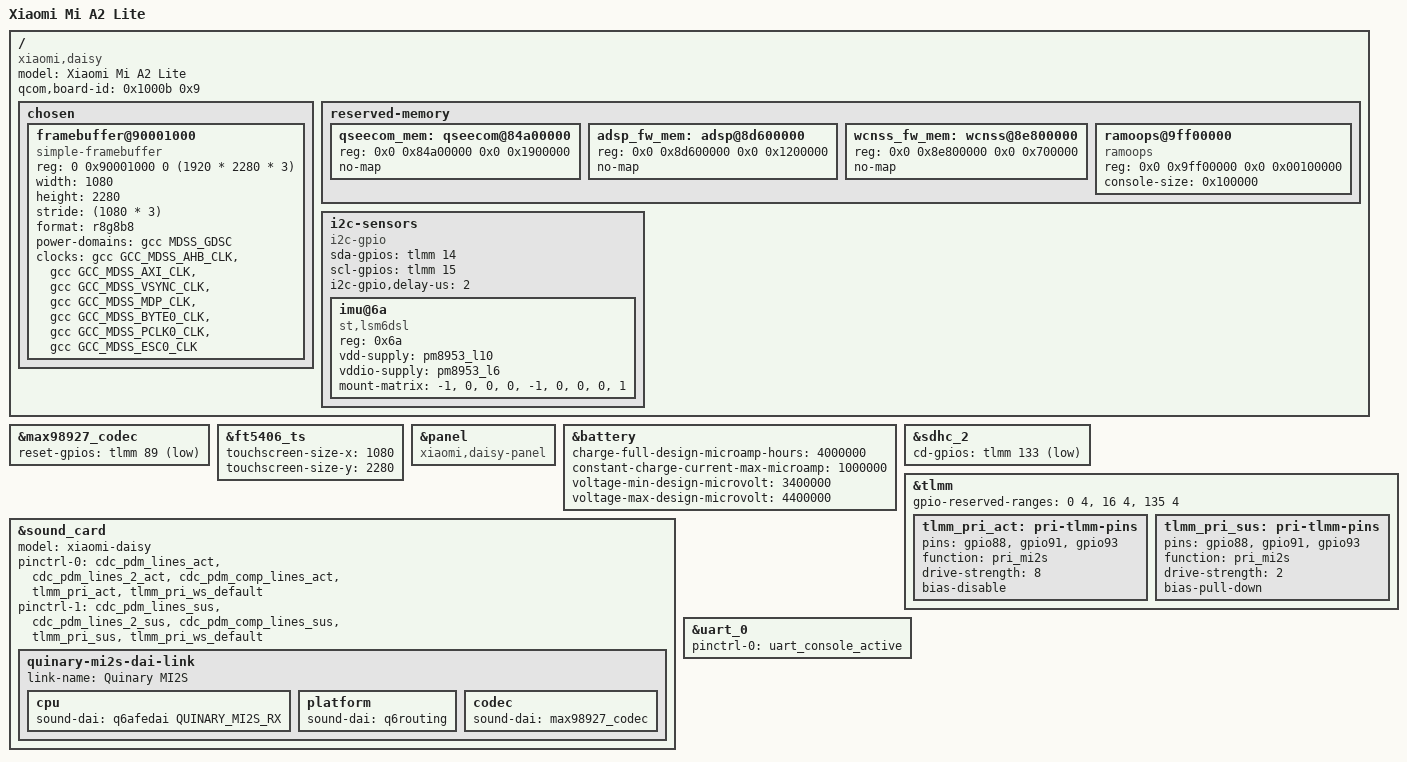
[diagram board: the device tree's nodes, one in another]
// SPDX-License-Identifier: BSD-3-Clause
/*
 * Copyright (c) 2022, Alejandro Tafalla
 */
/dts-v1/;

#include "msm8953-xiaomi-common.dtsi"

/delete-node/ &adsp_fw_mem;
/delete-node/ &qseecom_mem;
/delete-node/ &wcnss_fw_mem;

/ {
	model = "Xiaomi Mi A2 Lite";
	compatible = "xiaomi,daisy", "qcom,msm8953";
	qcom,board-id = <0x1000b 0x9>;

	chosen {
		#address-cells = <2>;
		#size-cells = <2>;
		ranges;

		framebuffer@90001000 {
			compatible = "simple-framebuffer";
			reg = <0 0x90001000 0 (1920 * 2280 * 3)>;

			width = <1080>;
			height = <2280>;
			stride = <(1080 * 3)>;
			format = "r8g8b8";

			power-domains = <&gcc MDSS_GDSC>;

			clocks = <&gcc GCC_MDSS_AHB_CLK>,
				 <&gcc GCC_MDSS_AXI_CLK>,
				 <&gcc GCC_MDSS_VSYNC_CLK>,
				 <&gcc GCC_MDSS_MDP_CLK>,
				 <&gcc GCC_MDSS_BYTE0_CLK>,
				 <&gcc GCC_MDSS_PCLK0_CLK>,
				 <&gcc GCC_MDSS_ESC0_CLK>;
		};
	};

	reserved-memory {
		qseecom_mem: qseecom@84a00000 {
			reg = <0x0 0x84a00000 0x0 0x1900000>;
			no-map;
		};

		adsp_fw_mem: adsp@8d600000 {
			reg = <0x0 0x8d600000 0x0 0x1200000>;
			no-map;
		};

		wcnss_fw_mem: wcnss@8e800000 {
			reg = <0x0 0x8e800000 0x0 0x700000>;
			no-map;
		};

		ramoops@9ff00000 {
			compatible = "ramoops";
			reg = <0x0 0x9ff00000 0x0 0x00100000>;
			console-size = <0x100000>;
		};
	};

	/*
	 * We bitbang on &i2c_4 because BLSP is protected by TZ as sensors are
	 * normally proxied via ADSP firmware. GPIOs aren't protected.
	 */
	i2c-sensors {
		compatible = "i2c-gpio";
		sda-gpios = <&tlmm 14 (GPIO_ACTIVE_HIGH|GPIO_OPEN_DRAIN)>;
		scl-gpios = <&tlmm 15 (GPIO_ACTIVE_HIGH|GPIO_OPEN_DRAIN)>;
		i2c-gpio,delay-us = <2>; /* ~100 kHz */
		#address-cells = <1>;
		#size-cells = <0>;

		imu@6a {
			compatible = "st,lsm6dsl";
			reg = <0x6a>;
			vdd-supply = <&pm8953_l10>;
			vddio-supply = <&pm8953_l6>;
			mount-matrix = "-1", "0", "0",
					"0", "-1", "0",
					"0", "0", "1";
		};
	};
};

&max98927_codec {
	status = "okay";

	reset-gpios = <&tlmm 89 GPIO_ACTIVE_LOW>;
};

&ft5406_ts {
	status = "okay";

	touchscreen-size-x = <1080>;
	touchscreen-size-y = <2280>;
};

&panel {
	compatible = "xiaomi,daisy-panel";
};

&battery {
	charge-full-design-microamp-hours = <4000000>;
	constant-charge-current-max-microamp = <1000000>;
	voltage-min-design-microvolt = <3400000>;
	voltage-max-design-microvolt = <4400000>;
};

&sdhc_2 {
	cd-gpios = <&tlmm 133 GPIO_ACTIVE_LOW>;
};

&sound_card {
	status = "okay";

	model = "xiaomi-daisy";

	pinctrl-names = "default", "sleep";
	pinctrl-0 = <&cdc_pdm_lines_act
			&cdc_pdm_lines_2_act
			&cdc_pdm_comp_lines_act
			&tlmm_pri_act
			&tlmm_pri_ws_default>;
	pinctrl-1 = <&cdc_pdm_lines_sus
			&cdc_pdm_lines_2_sus
			&cdc_pdm_comp_lines_sus
			&tlmm_pri_sus
			&tlmm_pri_ws_default>;

	quinary-mi2s-dai-link {
		link-name = "Quinary MI2S";
		cpu {
			sound-dai = <&q6afedai QUINARY_MI2S_RX>;
		};

		platform {
			sound-dai = <&q6routing>;
		};

		codec {
			sound-dai = <&max98927_codec>;
		};
	};
};

&tlmm {
	gpio-reserved-ranges = <0 4>, <16 4>, <135 4>;

	tlmm_pri_act: pri-tlmm-pins {
		pins = "gpio88", "gpio91", "gpio93";
		function = "pri_mi2s";
		drive-strength = <8>;
		bias-disable;
	};

	tlmm_pri_sus: pri-tlmm-pins {
		pins = "gpio88", "gpio91", "gpio93";
		function = "pri_mi2s";
		drive-strength = <2>;
		bias-pull-down;
	};
};

&uart_0 {
	pinctrl-names = "default";
	pinctrl-0 = <&uart_console_active>;

	status = "okay";
};
